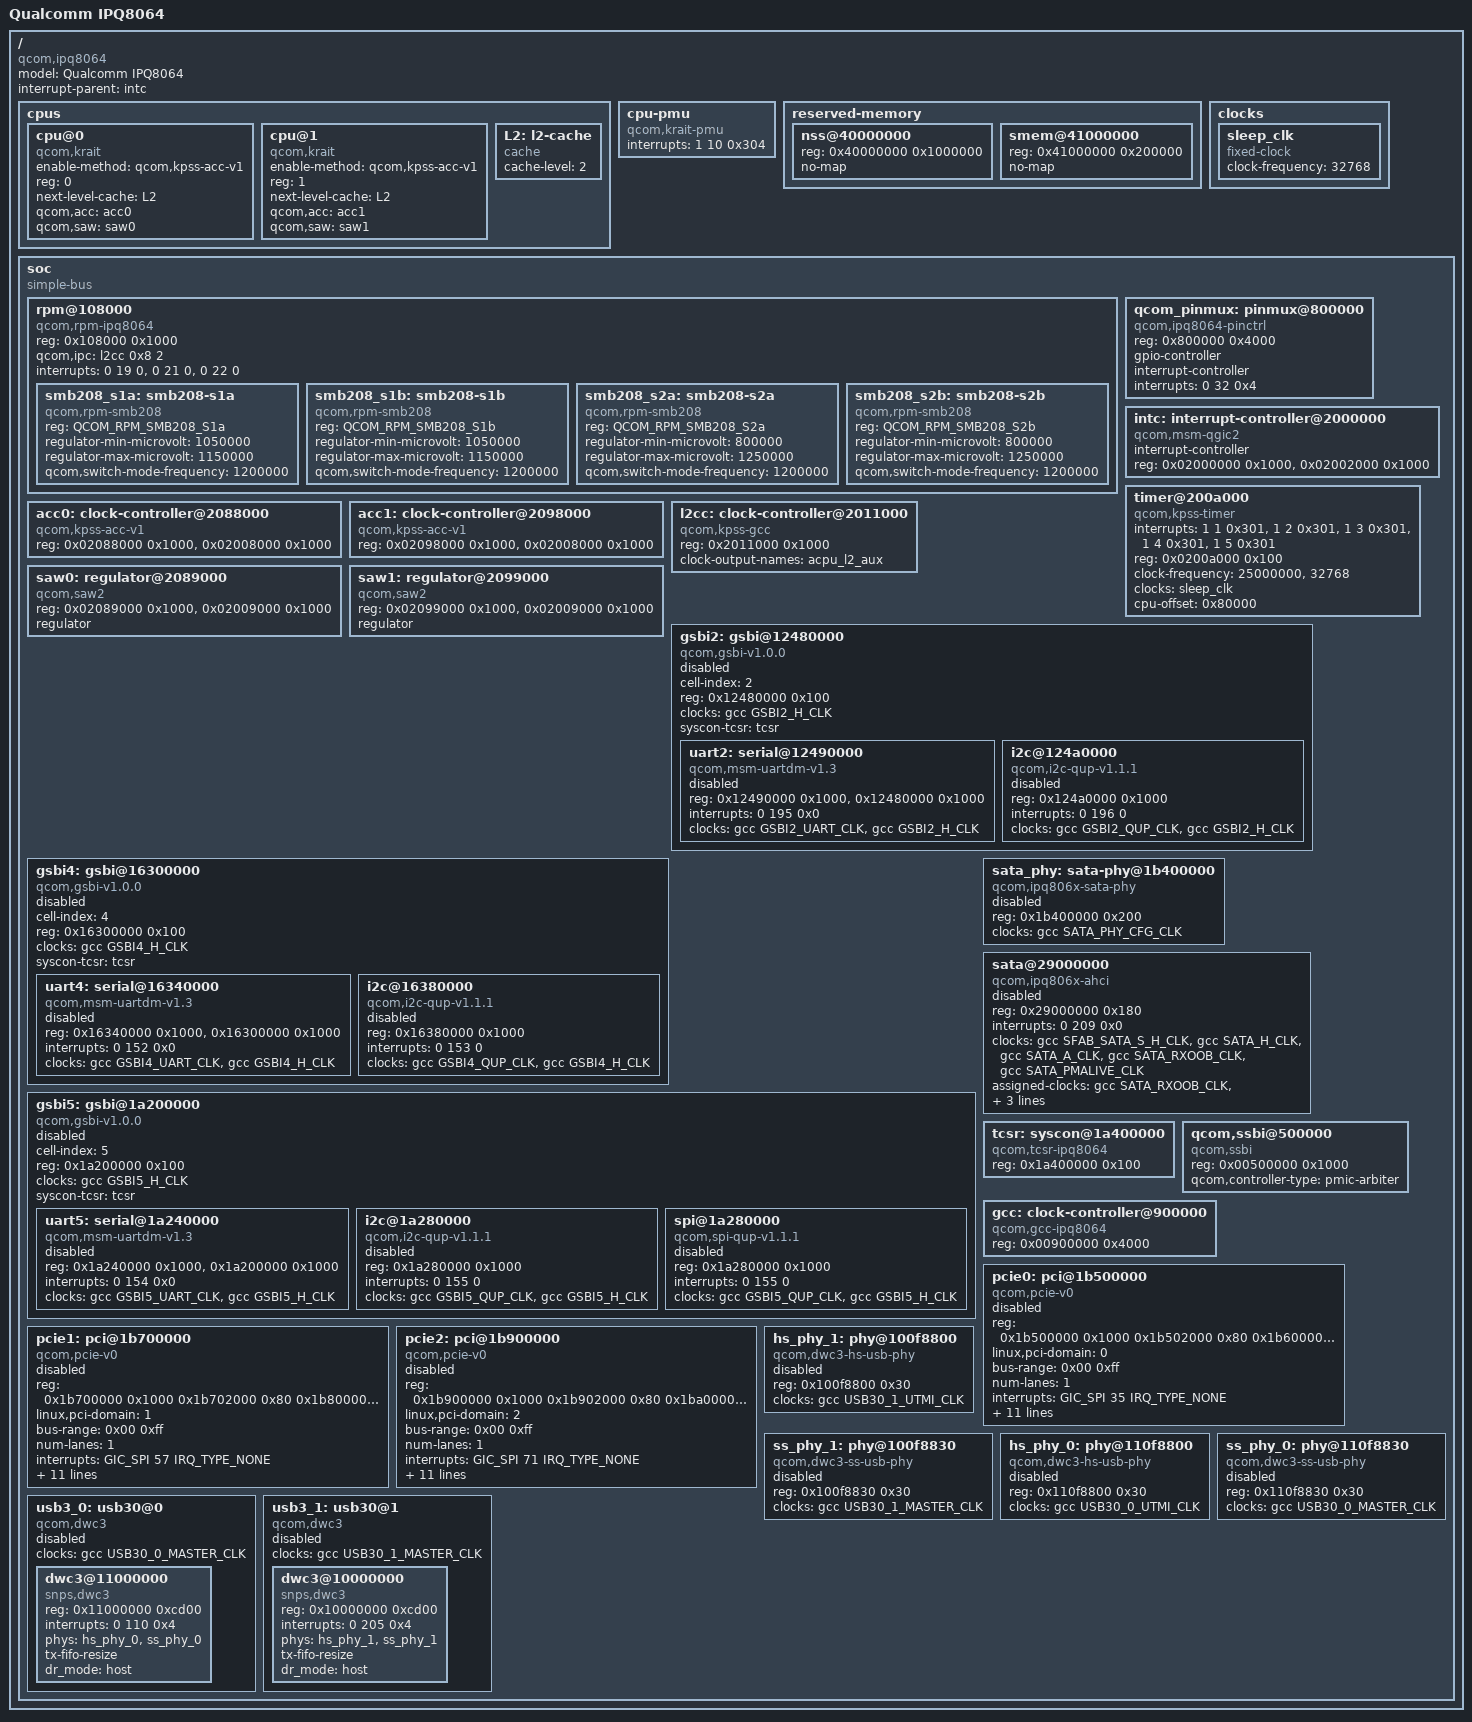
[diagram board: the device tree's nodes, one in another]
/dts-v1/;

#include "skeleton.dtsi"
#include <dt-bindings/clock/qcom,gcc-ipq806x.h>
#include <dt-bindings/mfd/qcom-rpm.h>
#include <dt-bindings/soc/qcom,gsbi.h>
#include <dt-bindings/reset/qcom,gcc-ipq806x.h>
#include <dt-bindings/interrupt-controller/arm-gic.h>

/ {
	model = "Qualcomm IPQ8064";
	compatible = "qcom,ipq8064";
	interrupt-parent = <&intc>;

	cpus {
		#address-cells = <1>;
		#size-cells = <0>;

		cpu@0 {
			compatible = "qcom,krait";
			enable-method = "qcom,kpss-acc-v1";
			device_type = "cpu";
			reg = <0>;
			next-level-cache = <&L2>;
			qcom,acc = <&acc0>;
			qcom,saw = <&saw0>;
		};

		cpu@1 {
			compatible = "qcom,krait";
			enable-method = "qcom,kpss-acc-v1";
			device_type = "cpu";
			reg = <1>;
			next-level-cache = <&L2>;
			qcom,acc = <&acc1>;
			qcom,saw = <&saw1>;
		};

		L2: l2-cache {
			compatible = "cache";
			cache-level = <2>;
		};
	};

	cpu-pmu {
		compatible = "qcom,krait-pmu";
		interrupts = <1 10 0x304>;
	};

	reserved-memory {
		#address-cells = <1>;
		#size-cells = <1>;
		ranges;

		nss@40000000 {
			reg = <0x40000000 0x1000000>;
			no-map;
		};

		smem@41000000 {
			reg = <0x41000000 0x200000>;
			no-map;
		};
	};

	clocks {
		sleep_clk: sleep_clk {
			compatible = "fixed-clock";
			clock-frequency = <32768>;
			#clock-cells = <0>;
		};
	};

	soc: soc {
		#address-cells = <1>;
		#size-cells = <1>;
		ranges;
		compatible = "simple-bus";

		rpm@108000 {
			compatible = "qcom,rpm-ipq8064";
			reg = <0x108000 0x1000>;
			qcom,ipc = <&l2cc 0x8 2>;

			interrupts = <0 19 0>,
				     <0 21 0>,
				     <0 22 0>;
			interrupt-names = "ack",
					  "err",
					  "wakeup";

			#address-cells = <1>;
			#size-cells = <0>;

			smb208_s1a: smb208-s1a {
				compatible = "qcom,rpm-smb208";
				reg = <QCOM_RPM_SMB208_S1a>;

				regulator-min-microvolt = <1050000>;
				regulator-max-microvolt = <1150000>;

				qcom,switch-mode-frequency = <1200000>;

			};

			smb208_s1b: smb208-s1b {
				compatible = "qcom,rpm-smb208";
				reg = <QCOM_RPM_SMB208_S1b>;

				regulator-min-microvolt = <1050000>;
				regulator-max-microvolt = <1150000>;

				qcom,switch-mode-frequency = <1200000>;
			};

			smb208_s2a: smb208-s2a {
				compatible = "qcom,rpm-smb208";
				reg = <QCOM_RPM_SMB208_S2a>;

				regulator-min-microvolt = < 800000>;
				regulator-max-microvolt = <1250000>;

				qcom,switch-mode-frequency = <1200000>;
			};

			smb208_s2b: smb208-s2b {
				compatible = "qcom,rpm-smb208";
				reg = <QCOM_RPM_SMB208_S2b>;

				regulator-min-microvolt = < 800000>;
				regulator-max-microvolt = <1250000>;

				qcom,switch-mode-frequency = <1200000>;
			};
		};

		qcom_pinmux: pinmux@800000 {
			compatible = "qcom,ipq8064-pinctrl";
			reg = <0x800000 0x4000>;

			gpio-controller;
			#gpio-cells = <2>;
			interrupt-controller;
			#interrupt-cells = <2>;
			interrupts = <0 32 0x4>;
		};

		intc: interrupt-controller@2000000 {
			compatible = "qcom,msm-qgic2";
			interrupt-controller;
			#interrupt-cells = <3>;
			reg = <0x02000000 0x1000>,
			      <0x02002000 0x1000>;
		};

		timer@200a000 {
			compatible = "qcom,kpss-timer", "qcom,msm-timer";
			interrupts = <1 1 0x301>,
				     <1 2 0x301>,
				     <1 3 0x301>,
				     <1 4 0x301>,
				     <1 5 0x301>;
			reg = <0x0200a000 0x100>;
			clock-frequency = <25000000>,
					  <32768>;
			clocks = <&sleep_clk>;
			clock-names = "sleep";
			cpu-offset = <0x80000>;
		};

		acc0: clock-controller@2088000 {
			compatible = "qcom,kpss-acc-v1";
			reg = <0x02088000 0x1000>, <0x02008000 0x1000>;
		};

		acc1: clock-controller@2098000 {
			compatible = "qcom,kpss-acc-v1";
			reg = <0x02098000 0x1000>, <0x02008000 0x1000>;
		};

		l2cc: clock-controller@2011000 {
			compatible = "qcom,kpss-gcc", "syscon";
			reg = <0x2011000 0x1000>;
			clock-output-names = "acpu_l2_aux";
 		};
 
		saw0: regulator@2089000 {
			compatible = "qcom,saw2";
			reg = <0x02089000 0x1000>, <0x02009000 0x1000>;
			regulator;
		};

		saw1: regulator@2099000 {
			compatible = "qcom,saw2";
			reg = <0x02099000 0x1000>, <0x02009000 0x1000>;
			regulator;
		};

		gsbi2: gsbi@12480000 {
			compatible = "qcom,gsbi-v1.0.0";
			cell-index = <2>;
			reg = <0x12480000 0x100>;
			clocks = <&gcc GSBI2_H_CLK>;
			clock-names = "iface";
			#address-cells = <1>;
			#size-cells = <1>;
			ranges;
			status = "disabled";

			syscon-tcsr = <&tcsr>;

			uart2: serial@12490000 {
				compatible = "qcom,msm-uartdm-v1.3", "qcom,msm-uartdm";
				reg = <0x12490000 0x1000>,
				      <0x12480000 0x1000>;
				interrupts = <0 195 0x0>;
				clocks = <&gcc GSBI2_UART_CLK>, <&gcc GSBI2_H_CLK>;
				clock-names = "core", "iface";
				status = "disabled";
			};

			i2c@124a0000 {
				compatible = "qcom,i2c-qup-v1.1.1";
				reg = <0x124a0000 0x1000>;
				interrupts = <0 196 0>;

				clocks = <&gcc GSBI2_QUP_CLK>, <&gcc GSBI2_H_CLK>;
				clock-names = "core", "iface";
				status = "disabled";

				#address-cells = <1>;
				#size-cells = <0>;
			};

		};

		gsbi4: gsbi@16300000 {
			compatible = "qcom,gsbi-v1.0.0";
			cell-index = <4>;
			reg = <0x16300000 0x100>;
			clocks = <&gcc GSBI4_H_CLK>;
			clock-names = "iface";
			#address-cells = <1>;
			#size-cells = <1>;
			ranges;
			status = "disabled";

			syscon-tcsr = <&tcsr>;

			uart4: serial@16340000 {
				compatible = "qcom,msm-uartdm-v1.3", "qcom,msm-uartdm";
				reg = <0x16340000 0x1000>,
				      <0x16300000 0x1000>;
				interrupts = <0 152 0x0>;
				clocks = <&gcc GSBI4_UART_CLK>, <&gcc GSBI4_H_CLK>;
				clock-names = "core", "iface";
				status = "disabled";
			};

			i2c@16380000 {
				compatible = "qcom,i2c-qup-v1.1.1";
				reg = <0x16380000 0x1000>;
				interrupts = <0 153 0>;

				clocks = <&gcc GSBI4_QUP_CLK>, <&gcc GSBI4_H_CLK>;
				clock-names = "core", "iface";
				status = "disabled";

				#address-cells = <1>;
				#size-cells = <0>;
			};
		};

		gsbi5: gsbi@1a200000 {
			compatible = "qcom,gsbi-v1.0.0";
			cell-index = <5>;
			reg = <0x1a200000 0x100>;
			clocks = <&gcc GSBI5_H_CLK>;
			clock-names = "iface";
			#address-cells = <1>;
			#size-cells = <1>;
			ranges;
			status = "disabled";

			syscon-tcsr = <&tcsr>;

			uart5: serial@1a240000 {
				compatible = "qcom,msm-uartdm-v1.3", "qcom,msm-uartdm";
				reg = <0x1a240000 0x1000>,
				      <0x1a200000 0x1000>;
				interrupts = <0 154 0x0>;
				clocks = <&gcc GSBI5_UART_CLK>, <&gcc GSBI5_H_CLK>;
				clock-names = "core", "iface";
				status = "disabled";
			};

			i2c@1a280000 {
				compatible = "qcom,i2c-qup-v1.1.1";
				reg = <0x1a280000 0x1000>;
				interrupts = <0 155 0>;

				clocks = <&gcc GSBI5_QUP_CLK>, <&gcc GSBI5_H_CLK>;
				clock-names = "core", "iface";
				status = "disabled";

				#address-cells = <1>;
				#size-cells = <0>;
			};

			spi@1a280000 {
				compatible = "qcom,spi-qup-v1.1.1";
				reg = <0x1a280000 0x1000>;
				interrupts = <0 155 0>;

				clocks = <&gcc GSBI5_QUP_CLK>, <&gcc GSBI5_H_CLK>;
				clock-names = "core", "iface";
				status = "disabled";

				#address-cells = <1>;
				#size-cells = <0>;
			};
		};

		sata_phy: sata-phy@1b400000 {
			compatible = "qcom,ipq806x-sata-phy";
			reg = <0x1b400000 0x200>;

			clocks = <&gcc SATA_PHY_CFG_CLK>;
			clock-names = "cfg";

			#phy-cells = <0>;
			status = "disabled";
		};

		sata@29000000 {
			compatible = "qcom,ipq806x-ahci", "generic-ahci";
			reg = <0x29000000 0x180>;

			interrupts = <0 209 0x0>;

			clocks = <&gcc SFAB_SATA_S_H_CLK>,
				 <&gcc SATA_H_CLK>,
				 <&gcc SATA_A_CLK>,
				 <&gcc SATA_RXOOB_CLK>,
				 <&gcc SATA_PMALIVE_CLK>;
			clock-names = "slave_face", "iface", "core",
					"rxoob", "pmalive";

			assigned-clocks = <&gcc SATA_RXOOB_CLK>, <&gcc SATA_PMALIVE_CLK>;
			assigned-clock-rates = <100000000>, <100000000>;

			phys = <&sata_phy>;
			phy-names = "sata-phy";
			status = "disabled";
		};

		tcsr: syscon@1a400000 {
			compatible = "qcom,tcsr-ipq8064", "syscon";
			reg = <0x1a400000 0x100>;
		};

		qcom,ssbi@500000 {
			compatible = "qcom,ssbi";
			reg = <0x00500000 0x1000>;
			qcom,controller-type = "pmic-arbiter";
		};

		gcc: clock-controller@900000 {
			compatible = "qcom,gcc-ipq8064";
			reg = <0x00900000 0x4000>;
			#clock-cells = <1>;
			#reset-cells = <1>;
		};

		pcie0: pci@1b500000 {
			compatible = "qcom,pcie-v0";
			reg = <0x1b500000 0x1000
			       0x1b502000 0x80
			       0x1b600000 0x100
			       0x0ff00000 0x100000>;
			reg-names = "dbi", "elbi", "parf", "config";
			device_type = "pci";
			linux,pci-domain = <0>;
			bus-range = <0x00 0xff>;
			num-lanes = <1>;
			#address-cells = <3>;
			#size-cells = <2>;

			ranges = <0x81000000 0 0	  0x0fe00000 0 0x00100000   /* downstream I/O */
				  0x82000000 0 0x00000000 0x08000000 0 0x07e00000>; /* non-prefetchable memory */

			interrupts = <GIC_SPI 35 IRQ_TYPE_NONE>;
			interrupt-names = "msi";
			#interrupt-cells = <1>;
			interrupt-map-mask = <0 0 0 0x7>;
			interrupt-map = <0 0 0 1 &intc 0 36 IRQ_TYPE_LEVEL_HIGH>, /* int_a */
					<0 0 0 2 &intc 0 37 IRQ_TYPE_LEVEL_HIGH>, /* int_b */
					<0 0 0 3 &intc 0 38 IRQ_TYPE_LEVEL_HIGH>, /* int_c */
					<0 0 0 4 &intc 0 39 IRQ_TYPE_LEVEL_HIGH>; /* int_d */

			clocks = <&gcc PCIE_A_CLK>,
				 <&gcc PCIE_H_CLK>,
				 <&gcc PCIE_PHY_CLK>;
			clock-names = "core", "iface", "phy";

			resets = <&gcc PCIE_ACLK_RESET>,
				 <&gcc PCIE_HCLK_RESET>,
				 <&gcc PCIE_POR_RESET>,
				 <&gcc PCIE_PCI_RESET>,
				 <&gcc PCIE_PHY_RESET>;
			reset-names = "axi", "ahb", "por", "pci", "phy";

			status = "disabled";
		};

		pcie1: pci@1b700000 {
			compatible = "qcom,pcie-v0";
			reg = <0x1b700000 0x1000
			       0x1b702000 0x80
			       0x1b800000 0x100
			       0x31f00000 0x100000>;
			reg-names = "dbi", "elbi", "parf", "config";
			device_type = "pci";
			linux,pci-domain = <1>;
			bus-range = <0x00 0xff>;
			num-lanes = <1>;
			#address-cells = <3>;
			#size-cells = <2>;

			ranges = <0x81000000 0 0	  0x31e00000 0 0x00100000   /* downstream I/O */
				  0x82000000 0 0x00000000 0x2e000000 0 0x03e00000>; /* non-prefetchable memory */

			interrupts = <GIC_SPI 57 IRQ_TYPE_NONE>;
			interrupt-names = "msi";
			#interrupt-cells = <1>;
			interrupt-map-mask = <0 0 0 0x7>;
			interrupt-map = <0 0 0 1 &intc 0 58 IRQ_TYPE_LEVEL_HIGH>, /* int_a */
					<0 0 0 2 &intc 0 59 IRQ_TYPE_LEVEL_HIGH>, /* int_b */
					<0 0 0 3 &intc 0 60 IRQ_TYPE_LEVEL_HIGH>, /* int_c */
					<0 0 0 4 &intc 0 61 IRQ_TYPE_LEVEL_HIGH>; /* int_d */

			clocks = <&gcc PCIE_1_A_CLK>,
				 <&gcc PCIE_1_H_CLK>,
				 <&gcc PCIE_1_PHY_CLK>;
			clock-names = "core", "iface", "phy";

			resets = <&gcc PCIE_1_ACLK_RESET>,
				 <&gcc PCIE_1_HCLK_RESET>,
				 <&gcc PCIE_1_POR_RESET>,
				 <&gcc PCIE_1_PCI_RESET>,
				 <&gcc PCIE_1_PHY_RESET>;
			reset-names = "axi", "ahb", "por", "pci", "phy";

			status = "disabled";
		};

		pcie2: pci@1b900000 {
			compatible = "qcom,pcie-v0";
			reg = <0x1b900000 0x1000
			       0x1b902000 0x80
			       0x1ba00000 0x100
			       0x35f00000 0x100000>;
			reg-names = "dbi", "elbi", "parf", "config";
			device_type = "pci";
			linux,pci-domain = <2>;
			bus-range = <0x00 0xff>;
			num-lanes = <1>;
			#address-cells = <3>;
			#size-cells = <2>;

			ranges = <0x81000000 0 0	  0x35e00000 0 0x00100000   /* downstream I/O */
				  0x82000000 0 0x00000000 0x32000000 0 0x03e00000>; /* non-prefetchable memory */

			interrupts = <GIC_SPI 71 IRQ_TYPE_NONE>;
			interrupt-names = "msi";
			#interrupt-cells = <1>;
			interrupt-map-mask = <0 0 0 0x7>;
			interrupt-map = <0 0 0 1 &intc 0 72 IRQ_TYPE_LEVEL_HIGH>, /* int_a */
					<0 0 0 2 &intc 0 73 IRQ_TYPE_LEVEL_HIGH>, /* int_b */
					<0 0 0 3 &intc 0 74 IRQ_TYPE_LEVEL_HIGH>, /* int_c */
					<0 0 0 4 &intc 0 75 IRQ_TYPE_LEVEL_HIGH>; /* int_d */

			clocks = <&gcc PCIE_2_A_CLK>,
				 <&gcc PCIE_2_H_CLK>,
				 <&gcc PCIE_2_PHY_CLK>;
			clock-names = "core", "iface", "phy";

			resets = <&gcc PCIE_2_ACLK_RESET>,
				 <&gcc PCIE_2_HCLK_RESET>,
				 <&gcc PCIE_2_POR_RESET>,
				 <&gcc PCIE_2_PCI_RESET>,
				 <&gcc PCIE_2_PHY_RESET>;
			reset-names = "axi", "ahb", "por", "pci", "phy";

			status = "disabled";
		};

		hs_phy_1: phy@100f8800 {
			compatible = "qcom,dwc3-hs-usb-phy";
			reg = <0x100f8800 0x30>;
			clocks = <&gcc USB30_1_UTMI_CLK>;
			clock-names = "ref";
			#phy-cells = <0>;

			status = "disabled";
		};

		ss_phy_1: phy@100f8830 {
			compatible = "qcom,dwc3-ss-usb-phy";
			reg = <0x100f8830 0x30>;
			clocks = <&gcc USB30_1_MASTER_CLK>;
			clock-names = "ref";
			#phy-cells = <0>;

			status = "disabled";
		};

		hs_phy_0: phy@110f8800 {
			compatible = "qcom,dwc3-hs-usb-phy";
			reg = <0x110f8800 0x30>;
			clocks = <&gcc USB30_0_UTMI_CLK>;
			clock-names = "ref";
			#phy-cells = <0>;

			status = "disabled";
		};

		ss_phy_0: phy@110f8830 {
			compatible = "qcom,dwc3-ss-usb-phy";
			reg = <0x110f8830 0x30>;
			clocks = <&gcc USB30_0_MASTER_CLK>;
			clock-names = "ref";
			#phy-cells = <0>;

			status = "disabled";
		};

		usb3_0: usb30@0 {
			compatible = "qcom,dwc3";
			#address-cells = <1>;
			#size-cells = <1>;
			clocks = <&gcc USB30_0_MASTER_CLK>;
			clock-names = "core";

			ranges;

			status = "disabled";

			dwc3@11000000 {
				compatible = "snps,dwc3";
				reg = <0x11000000 0xcd00>;
				interrupts = <0 110 0x4>;
				phys = <&hs_phy_0>, <&ss_phy_0>;
				phy-names = "usb2-phy", "usb3-phy";
				tx-fifo-resize;
				dr_mode = "host";
			};
		};

		usb3_1: usb30@1 {
			compatible = "qcom,dwc3";
			#address-cells = <1>;
			#size-cells = <1>;
			clocks = <&gcc USB30_1_MASTER_CLK>;
			clock-names = "core";

			ranges;

			status = "disabled";

			dwc3@10000000 {
				compatible = "snps,dwc3";
				reg = <0x10000000 0xcd00>;
				interrupts = <0 205 0x4>;
				phys = <&hs_phy_1>, <&ss_phy_1>;
				phy-names = "usb2-phy", "usb3-phy";
				tx-fifo-resize;
				dr_mode = "host";
			};
		};
	};
};
